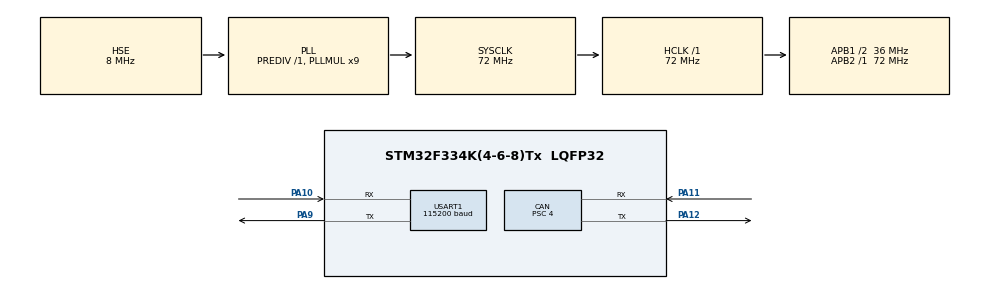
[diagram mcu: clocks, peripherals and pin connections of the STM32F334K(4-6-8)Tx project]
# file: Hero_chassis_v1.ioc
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CAN.BS1=CAN_BS1_3TQ
CAN.BS2=CAN_BS2_5TQ
CAN.CalculateTimeQuantum=111.11111111111111
CAN.Prescaler=4
Dma.Request0=USART1_RX
Dma.Request1=USART1_TX
Dma.USART1_RX.0.Direction=DMA_PERIPH_TO_MEMORY
Dma.USART1_RX.0.Instance=DMA1_Channel5
Dma.USART1_RX.0.MemDataAlignment=DMA_MDATAALIGN_BYTE
Dma.USART1_RX.0.MemInc=DMA_MINC_ENABLE
Dma.USART1_RX.0.Mode=DMA_CIRCULAR
Dma.USART1_RX.0.PeriphDataAlignment=DMA_PDATAALIGN_BYTE
Dma.USART1_RX.0.PeriphInc=DMA_PINC_DISABLE
Dma.USART1_RX.0.Priority=DMA_PRIORITY_LOW
Dma.USART1_TX.1.Direction=DMA_MEMORY_TO_PERIPH
Dma.USART1_TX.1.Instance=DMA1_Channel4
Dma.USART1_TX.1.MemDataAlignment=DMA_MDATAALIGN_BYTE
Dma.USART1_TX.1.MemInc=DMA_MINC_ENABLE
Dma.USART1_TX.1.Mode=DMA_CIRCULAR
Dma.USART1_TX.1.PeriphDataAlignment=DMA_PDATAALIGN_BYTE
Dma.USART1_TX.1.PeriphInc=DMA_PINC_DISABLE
Dma.USART1_TX.1.Priority=DMA_PRIORITY_LOW
FREERTOS.HEAP_NUMBER=4
FREERTOS.Tasks01=defaultTask,0,128,StartDefaultTask,Default,NULL,Dynamic,NULL,NULL
FREERTOS.configTOTAL_HEAP_SIZE=4196
Mcu.Family=STM32F3
Mcu.Name=STM32F334K(4-6-8)Tx
Mcu.Package=LQFP32
NVIC.CAN_RX0_IRQn=true\:5\:0\:false\:false\:true\:true\:true\:true
NVIC.CAN_TX_IRQn=true\:5\:0\:false\:false\:true\:true\:true\:true
NVIC.DMA1_Channel4_IRQn=true\:5\:0\:false\:false\:true\:true\:false\:true
NVIC.DMA1_Channel5_IRQn=true\:5\:0\:false\:false\:true\:true\:false\:true
NVIC.PriorityGroup=NVIC_PRIORITYGROUP_4
NVIC.TIM2_IRQn=true\:0\:0\:false\:false\:true\:false\:false\:true
NVIC.TimeBase=TIM2_IRQn
NVIC.TimeBaseIP=TIM2
NVIC.USART1_IRQn=true\:5\:0\:false\:false\:true\:true\:true\:true
PA10.Mode=Asynchronous
PA10.Signal=USART1_RX
PA11.Mode=Master
PA11.Signal=CAN_RX
PA12.Mode=Master
PA12.Signal=CAN_TX
PA13.Mode=Serial_Wire
PA13.Signal=SYS_JTMS-SWDIO
PA14.Mode=Serial_Wire
PA14.Signal=SYS_JTCK-SWCLK
PA9.Mode=Asynchronous
PA9.Signal=USART1_TX
PF0\ /\ OSC_IN.Mode=HSE-External-Oscillator
PF0\ /\ OSC_IN.Signal=RCC_OSC_IN
PF1\ /\ OSC_OUT.Mode=HSE-External-Oscillator
PF1\ /\ OSC_OUT.Signal=RCC_OSC_OUT
ProjectManager.HeapSize=0x200
ProjectManager.StackSize=0x400
ProjectManager.TargetToolchain=MDK-ARM V5.27
RCC.AHBFreq_Value=72000000
RCC.APB1CLKDivider=RCC_HCLK_DIV2
RCC.APB1Freq_Value=36000000
RCC.APB1TimFreq_Value=72000000
RCC.APB2Freq_Value=72000000
RCC.APB2TimFreq_Value=72000000
RCC.CortexFreq_Value=72000000
RCC.HCLKFreq_Value=72000000
RCC.HSE_VALUE=8000000
RCC.HSI_VALUE=8000000
RCC.PLLMUL=RCC_PLL_MUL9
RCC.PLLSourceVirtual=RCC_PLLSOURCE_HSE
RCC.SYSCLKFreq_VALUE=72000000
RCC.SYSCLKSourceVirtual=RCC_SYSCLKSOURCE_PLLCLK
USART1.BaudRate=115200
USART1.VirtualMode-Asynchronous=VM_ASYNC
VP_FREERTOS_VS_CMSIS_V1.Mode=CMSIS_V1
VP_SYS_VS_tim2.Mode=TIM2
board=custom

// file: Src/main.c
/* USER CODE BEGIN Header */
/**
  ******************************************************************************
  * @file           : main.c
  * @brief          : Main program body
  ******************************************************************************
  * @attention
  *
  * <h2><center>&copy; Copyright (c) 2020 STMicroelectronics.
  * All rights reserved.</center></h2>
  *
  * This software component is licensed by ST under Ultimate Liberty license
  * SLA0044, the "License"; You may not use this file except in compliance with
  * the License. You may obtain a copy of the License at:
  *                             www.st.com/SLA0044
  *
  ******************************************************************************
  */
/* USER CODE END Header */

#include "main.h"
#include "cmsis_os.h"
#include "can.h"
#include "dma.h"
#include "usart.h"
#include "gpio.h"

/* USER CODE BEGIN Includes */
#include "init.h"
/* USER CODE END Includes */

void SystemClock_Config(void);
void MX_FREERTOS_Init(void);

int main(void)
{

  /* MCU Configuration--------------------------------------------------------*/

  /* Reset of all peripherals, Initializes the Flash interface and the Systick. */
  HAL_Init();

  /* USER CODE BEGIN Init */
  hw_init();
  /* USER CODE END Init */

  /* Configure the system clock */
  SystemClock_Config();

  /* Initialize all configured peripherals */
  MX_GPIO_Init();
  MX_DMA_Init();
  MX_CAN_Init();
  MX_USART1_UART_Init();

  /* Call init function for freertos objects (in freertos.c) */
  MX_FREERTOS_Init();

  /* Start scheduler */
  osKernelStart();

  /* We should never get here as control is now taken by the scheduler */

  /* Infinite loop */
  while (1)
  {

  }
}

void SystemClock_Config(void)
{
  RCC_OscInitTypeDef RCC_OscInitStruct = {0};
  RCC_ClkInitTypeDef RCC_ClkInitStruct = {0};
  RCC_PeriphCLKInitTypeDef PeriphClkInit = {0};

  /** Initializes the CPU, AHB and APB busses clocks
  */
  RCC_OscInitStruct.OscillatorType = RCC_OSCILLATORTYPE_HSE;
  RCC_OscInitStruct.HSEState = RCC_HSE_ON;
  RCC_OscInitStruct.HSEPredivValue = RCC_HSE_PREDIV_DIV1;
  RCC_OscInitStruct.HSIState = RCC_HSI_ON;
  RCC_OscInitStruct.PLL.PLLState = RCC_PLL_ON;
  RCC_OscInitStruct.PLL.PLLSource = RCC_PLLSOURCE_HSE;
  RCC_OscInitStruct.PLL.PLLMUL = RCC_PLL_MUL9;
  if (HAL_RCC_OscConfig(&RCC_OscInitStruct) != HAL_OK)
  {
    Error_Handler();
  }
  /** Initializes the CPU, AHB and APB busses clocks
  */
  RCC_ClkInitStruct.ClockType = RCC_CLOCKTYPE_HCLK|RCC_CLOCKTYPE_SYSCLK
                              |RCC_CLOCKTYPE_PCLK1|RCC_CLOCKTYPE_PCLK2;
  RCC_ClkInitStruct.SYSCLKSource = RCC_SYSCLKSOURCE_PLLCLK;
  RCC_ClkInitStruct.AHBCLKDivider = RCC_SYSCLK_DIV1;
  RCC_ClkInitStruct.APB1CLKDivider = RCC_HCLK_DIV2;
  RCC_ClkInitStruct.APB2CLKDivider = RCC_HCLK_DIV1;

  if (HAL_RCC_ClockConfig(&RCC_ClkInitStruct, FLASH_LATENCY_2) != HAL_OK)
  {
    Error_Handler();
  }
  PeriphClkInit.PeriphClockSelection = RCC_PERIPHCLK_USART1;
  PeriphClkInit.Usart1ClockSelection = RCC_USART1CLKSOURCE_PCLK1;
  if (HAL_RCCEx_PeriphCLKConfig(&PeriphClkInit) != HAL_OK)
  {
    Error_Handler();
  }
}

void HAL_TIM_PeriodElapsedCallback(TIM_HandleTypeDef *htim)
{
  if (htim->Instance == TIM2) {
    HAL_IncTick();
  }
}

void Error_Handler(void)
{
}

/************************ (C) COPYRIGHT STMicroelectronics *****END OF FILE****/
